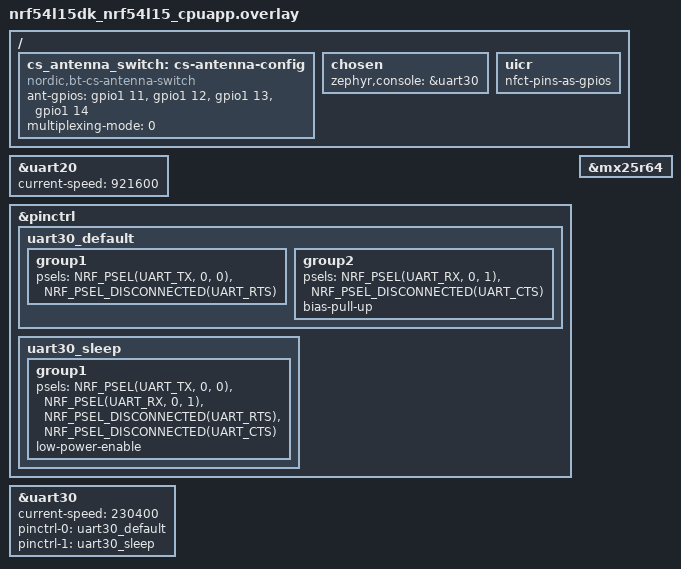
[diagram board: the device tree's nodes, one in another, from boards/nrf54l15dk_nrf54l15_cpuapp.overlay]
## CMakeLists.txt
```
#
# Copyright (c) 2024 Nordic Semiconductor
#
# SPDX-License-Identifier: LicenseRef-Nordic-5-Clause
#

cmake_minimum_required(VERSION 3.20.0)

find_package(Zephyr REQUIRED HINTS $ENV{ZEPHYR_BASE})
project(301ini)
# 自动查找 src/ 根目录下的所有 .c 文件
FILE(GLOB app_sources src/*.c)
# 手动添加 src/flash/ 子目录中的文件
FILE(GLOB flash_sources src/flash/*.c)
FILE(GLOB button_led_sources src/interface/*.c)

# NORDIC SDK APP START
target_sources(app PRIVATE
	${app_sources}
	${flash_sources}
	${button_led_sources}
)
# NORDIC SDK APP END
```

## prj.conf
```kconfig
#
# Copyright (c) 2024 Nordic Semiconductor ASA
#
# SPDX-License-Identifier: LicenseRef-Nordic-5-Clause
#
# 相对更底层的配置
CONFIG_SYSTEM_WORKQUEUE_STACK_SIZE=4096
CONFIG_MAIN_STACK_SIZE=4096
CONFIG_ASSERT=y

# 似乎是适用于官方DK和示例代码的配置
CONFIG_NCS_SAMPLES_DEFAULTS=y
CONFIG_DK_LIBRARY=y

# BT开头的一般都是蓝牙相关的配置
CONFIG_BT=y
CONFIG_BT_SMP=y
CONFIG_BT_CENTRAL=y
CONFIG_BT_MAX_CONN=1
CONFIG_BT_BONDABLE=n

CONFIG_BT_GATT_CLIENT=y
CONFIG_BT_GATT_DYNAMIC_DB=y

CONFIG_BT_CHANNEL_SOUNDING=y
CONFIG_BT_RAS=y
CONFIG_BT_RAS_RREQ=y

CONFIG_BT_SCAN=y
CONFIG_BT_SCAN_FILTER_ENABLE=y
CONFIG_BT_SCAN_UUID_CNT=1

# The Ranging Profile recommends a MTU of at least 247 octets.
CONFIG_BT_L2CAP_TX_MTU=498
CONFIG_BT_BUF_ACL_TX_SIZE=502
CONFIG_BT_BUF_ACL_RX_SIZE=502
CONFIG_BT_ATT_PREPARE_COUNT=3
CONFIG_BT_CTLR_DATA_LENGTH_MAX=251

# This reduces RAM usage. Additional RAM is needed to support optional
# features such as mode 3 or multiantenna. Change or remove these if
# using those features
CONFIG_BT_RAS_MODE_3_SUPPORTED=n
CONFIG_BT_RAS_MAX_ANTENNA_PATHS=1
CONFIG_BT_CTLR_SDC_CS_MAX_ANTENNA_PATHS=1
CONFIG_BT_CTLR_SDC_CS_NUM_ANTENNAS=1
CONFIG_BT_CTLR_SDC_CS_STEP_MODE3=n

# This size assumes the largest step size is mode 2 with one antenna path:
# 12 bytes * 160 steps in a subevent. Change or remove this if using mode 3
# or multiantenna.
CONFIG_BT_CHANNEL_SOUNDING_REASSEMBLY_BUFFER_SIZE=1920

# This allows CS and ACL to use different PHYs
CONFIG_BT_TRANSMIT_POWER_CONTROL=y

# This improves the performance of floating-point operations
CONFIG_FPU=y
CONFIG_FPU_SHARING=y

CONFIG_CBPRINTF_FP_SUPPORT=y

CONFIG_BT_CS_DE=y
CONFIG_BT_CS_DE_512_NFFT=y

# Console
CONFIG_CONSOLE=y
CONFIG_UART_CONSOLE=y
CONFIG_RTT_CONSOLE=n

# 这是启用非阻塞异步日志输出的
# 0 OFF
# 1 ERROR
# 2 WARNING
# 3 INFO
# 4 DEBUG
CONFIG_LOG=y
CONFIG_LOG_DEFAULT_LEVEL=3
CONFIG_LOG_MODE_DEFERRED=y
CONFIG_LOG_BACKEND_UART=y
CONFIG_LOG_BUFFER_SIZE=65536     
CONFIG_LOG_PROCESS_TRIGGER_THRESHOLD=256
CONFIG_LOG_PRINTK=y

CONFIG_LOG_BACKEND_RTT=n
CONFIG_LOG_BACKEND_UART=y
CONFIG_LOG_MODE_MINIMAL=y
CONFIG_LOG_MODE_IMMEDIATE=y

CONFIG_BT_CTLR_TX_PWR_PLUS_8=y
# 启用flash
CONFIG_FLASH=y

# QSPI Flash DMA配置
CONFIG_DMA=y
# CONFIG_NRFX_QSPI=y
# CONFIG_NRFX_QSPI_DMA=y

# Flash与蓝牙同步优化配置
CONFIG_SOC_FLASH_NRF_RADIO_SYNC_MPSL=y
CONFIG_MPSL_TIMESLOT_SESSION_COUNT=2

# Flash性能优化
# CONFIG_FLASH_PAGE_LAYOUT=y
# CONFIG_FLASH_MAP=y
# CONFIG_FLASH_HAS_DRIVER_ENABLED=y
```

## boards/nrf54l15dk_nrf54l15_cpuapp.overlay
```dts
/*
 * Copyright (c) 2025 Nordic Semiconductor ASA
 *
 * SPDX-License-Identifier: LicenseRef-Nordic-5-Clause
 */

/ {
	cs_antenna_switch: cs-antenna-config {
		status = "okay";
		compatible = "nordic,bt-cs-antenna-switch";
		ant-gpios = <&gpio1 11 (GPIO_ACTIVE_HIGH)>,
			    <&gpio1 12 (GPIO_ACTIVE_HIGH)>,
			    <&gpio1 13 (GPIO_ACTIVE_HIGH)>,
			    <&gpio1 14 (GPIO_ACTIVE_HIGH)>;
		multiplexing-mode = <0>;
	};

	chosen {
		/delete-property/ zephyr,console;
		/delete-property/ zephyr,shell-uart;
		/delete-property/ zephyr,uart-mcumgr;
		/delete-property/ zephyr,bt-mon-uart;
		/delete-property/ zephyr,bt-c2h-uart;
		zephyr,console = &uart30;
	};

	uicr { 
		nfct-pins-as-gpios; 
	};
};

&uart20 {
	current-speed = <921600>;
};

&pinctrl {
	uart30_default: uart30_default {
		group1 {
			psels = <NRF_PSEL(UART_TX, 0, 0)>,
			<NRF_PSEL_DISCONNECTED(UART_RTS)>;
		};
		group2 {
			psels = <NRF_PSEL(UART_RX, 0, 1)>,
			<NRF_PSEL_DISCONNECTED(UART_CTS)>;
			bias-pull-up;
		};
	};

	uart30_sleep: uart30_sleep {
		group1 {
			psels = <NRF_PSEL(UART_TX, 0, 0)>,
				<NRF_PSEL(UART_RX, 0, 1)>,
				<NRF_PSEL_DISCONNECTED(UART_RTS)>,
				<NRF_PSEL_DISCONNECTED(UART_CTS)>;
			low-power-enable;
		};
	};
};


&uart30 {
	current-speed = <230400>;
	pinctrl-0 = <&uart30_default>;
	pinctrl-1 = <&uart30_sleep>;
	pinctrl-names = "default", "sleep";
	/delete-property/ rts-pin;
	/delete-property/ cts-pin;	
	status = "okay";
};
&mx25r64 {
	status = "okay";

};
```

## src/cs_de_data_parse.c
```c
#include "cs_de_data_parse.h"
#include <bluetooth/cs_de.h>
#include <zephyr/logging/log.h>

LOG_MODULE_REGISTER(step_data_parse, CONFIG_LOG_DEFAULT_LEVEL);

void print_report(const cs_de_report_t *r, int max_output_channels) {
  // 内联role、quality、tone的字符串转换
  const char *role_str;
  switch (r->role) {
  case BT_CONN_LE_CS_ROLE_INITIATOR:
    role_str = "INITIATOR";
    break;
  case BT_CONN_LE_CS_ROLE_REFLECTOR:
    role_str = "REFLECTOR";
    break;
  default:
    role_str = "UNKNOWN";
    break;
  }

  LOG_INF("role=%s, n_ap=%d", role_str, r->n_ap);
  LOG_INF("rtt_accumulated_half_ns=%d, rtt_count=%d",
          r->rtt_accumulated_half_ns, r->rtt_count);

  for (int ap = 0; ap < r->n_ap; ap++) {
    const char *tone_str = (r->tone_quality[ap] == CS_DE_TONE_QUALITY_OK) ? "OK"
                           : (r->tone_quality[ap] == CS_DE_TONE_QUALITY_BAD)
                               ? "BAD"
                               : "UNKNOWN";
    LOG_INF("-- Antenna Path %d --", ap);
    LOG_INF("  Tone quality: %s", tone_str);
    LOG_INF("  Distance (ifft/phase_slope/rtt/best): %.3f / %.3f / %.3f / %.3f",
            r->distance_estimates[ap].ifft,
            r->distance_estimates[ap].phase_slope,
            r->distance_estimates[ap].rtt, r->distance_estimates[ap].best);
    for (int ch = 0; ch < max_output_channels; ch++) {
      LOG_INF(
          "  IQ[%d]: i_local=%.5f, q_local=%.5f, i_remote=%.5f, q_remote=%.5f",
          ch, r->iq_tones[ap].i_local[ch], r->iq_tones[ap].q_local[ch],
          r->iq_tones[ap].i_remote[ch], r->iq_tones[ap].q_remote[ch]);
    }
  }
}

void print_store_cs_de_report(const store_cs_de_report_t *s,
                              int max_output_channels) {
  LOG_INF("== store_cs_de_report_t ==");
  LOG_INF("report_index: %u", s->report_index);
  LOG_INF("timestamp_ms: %llu", s->timestamp_ms);
  print_report(&s->report, max_output_channels);
}

void store_cs_de_report(cs_de_report_t *p_report) {
  // 存储原始数据
  // 存储原始数据
}

void print_report_basic(const cs_de_report_t *r, int max_output_channels) {
  // 内联role、quality、tone的字符串转换
  const char *role_str;
  switch (r->role) {
  case BT_CONN_LE_CS_ROLE_INITIATOR:
    role_str = "INITIATOR";
    break;
  case BT_CONN_LE_CS_ROLE_REFLECTOR:
    role_str = "REFLECTOR";
    break;
  default:
    role_str = "UNKNOWN";
    break;
  }

  LOG_INF("role=%s, n_ap=%d, rtt_accumulated_half_ns=%d, rtt_count=%d",
          role_str, r->n_ap, r->rtt_accumulated_half_ns, r->rtt_count);

  for (int ap = 0; ap < r->n_ap; ap++) {
    const char *tone_str = (r->tone_quality[ap] == CS_DE_TONE_QUALITY_OK) ? "OK"
                           : (r->tone_quality[ap] == CS_DE_TONE_QUALITY_BAD)
                               ? "BAD"
                               : "UNKNOWN";
    
    LOG_INF("AP%d: quality=%s, dist(ifft/phase/rtt/best)=%.3f/%.3f/%.3f/%.3f",
            ap, tone_str,
            r->distance_estimates[ap].ifft,
            r->distance_estimates[ap].phase_slope,
            r->distance_estimates[ap].rtt, 
            r->distance_estimates[ap].best);
    
    // 分块打印IQ数据，避免缓冲区溢出
    const int channels_per_line = 8; // 每行8个通道
    const int max_buffer_size = 256; // 安全的缓冲区大小
    
    for (int ch_start = 0; ch_start < max_output_channels; ch_start += channels_per_line) {
      char iq_buffer[max_buffer_size];
      int offset = 0;
      
      offset += snprintf(iq_buffer + offset, sizeof(iq_buffer) - offset, 
                        "AP%d IQ[%d-%d]: ", ap, ch_start, 
                        (ch_start + channels_per_line - 1 < max_output_channels) ? 
                        ch_start + channels_per_line - 1 : max_output_channels - 1);
      
      int ch_end = (ch_start + channels_per_line < max_output_channels) ? 
                   ch_start + channels_per_line : max_output_channels;
      
      for (int ch = ch_start; ch < ch_end; ch++) {
        if (ch > ch_start) {
          offset += snprintf(iq_buffer + offset, sizeof(iq_buffer) - offset, " | ");
        }
        offset += snprintf(iq_buffer + offset, sizeof(iq_buffer) - offset,
                          "ch%d(i%.1f,q%.1f,i%.1f,q%.1f)", 
                          ch,
                          r->iq_tones[ap].i_local[ch],
                          r->iq_tones[ap].q_local[ch],
                          r->iq_tones[ap].i_remote[ch],
                          r->iq_tones[ap].q_remote[ch]);
      }
      
      LOG_INF("%s", iq_buffer);
    }
  }
}

void print_store_cs_de_report_basic(const store_cs_de_report_t *s,
                                   int max_output_channels) {
  LOG_INF("== Basic Report == index:%llu, timestamp:%llu", 
          s->report_index, s->timestamp_ms);
  print_report_fast(&s->report, max_output_channels);
  LOG_INF("== End Report ==");
}


#define IQ_LINE_CHUNK 512     // 单次输出最大字节数，按需调整
#define IQ_PRECISION 1        // 小数位数，1 位更紧凑更快
void print_report_fast(const cs_de_report_t *r, int max_output_channels) {
  // 内联role、quality、tone的字符串转换
  const char *role_str;
  switch (r->role) {
  case BT_CONN_LE_CS_ROLE_INITIATOR:
    role_str = "INITIATOR";
    break;
  case BT_CONN_LE_CS_ROLE_REFLECTOR:
    role_str = "REFLECTOR";
    break;
  default:
    role_str = "UNKNOWN";
    break;
  }

  LOG_INF("role=%s, n_ap=%d", role_str, r->n_ap);
  LOG_INF("rtt_accumulated_half_ns=%d, rtt_count=%d",
          r->rtt_accumulated_half_ns, r->rtt_count);

  for (int ap = 0; ap < r->n_ap; ap++) {
    const char *tone_str = (r->tone_quality[ap] == CS_DE_TONE_QUALITY_OK) ? "OK"
                           : (r->tone_quality[ap] == CS_DE_TONE_QUALITY_BAD)
                               ? "BAD"
                               : "UNKNOWN";
    LOG_INF("-- Antenna Path %d --", ap);
    LOG_INF("Tone=%s Dist(ifft/phase_slope/rtt/best)=%.3f/%.3f/%.3f/%.3f",
            tone_str,
            r->distance_estimates[ap].ifft,
            r->distance_estimates[ap].phase_slope,
            r->distance_estimates[ap].rtt,
            r->distance_estimates[ap].best);

    // 紧凑的 IQ 多信道合并输出
    char buf[IQ_LINE_CHUNK];
    size_t off = 0;

    // 先输出一个前缀，便于解析（可选）
    int n = snprintk(buf + off, sizeof(buf) - off, "IQ: ");
    if (n < 0) {
      // 格式化错误，直接跳过本 ap
      continue;
    }
    off += (size_t)n;

    for (int ch = 0; ch < max_output_channels; ch++) {
      // 每个信道的紧凑片段；为减少体积与格式化开销，默认 1 位小数
      n = snprintk(
          buf + off, sizeof(buf) - off,
          // "ch:%d,il:%.*f,ql:%.*f,ir:%.*f,qr:%.*f;",
          "ch:%d:%.*f,%.*f,%.*f,%.*f;",
          ch,
          IQ_PRECISION, r->iq_tones[ap].i_local[ch],
          IQ_PRECISION, r->iq_tones[ap].q_local[ch],
          IQ_PRECISION, r->iq_tones[ap].i_remote[ch],
          IQ_PRECISION, r->iq_tones[ap].q_remote[ch]);

      if (n < 0) {
        // 格式化错误，提前结束
        break;
      }

      // 如果这次写入会溢出缓冲区，先把已有内容打出去，再把当前信道重写入
      if ((size_t)n >= sizeof(buf) - off) {
        buf[off] = '\0';
        LOG_INF("%s", buf);
        off = 0;

        // 重新写入当前信道
        n = snprintk(
            buf + off, sizeof(buf) - off,
            // "ch:%d,il:%.*f,ql:%.*f,ir:%.*f,qr:%.*f;",
            "ch:%d:%.*f,%.*f,%.*f,%.*f;",
            ch,
            IQ_PRECISION, r->iq_tones[ap].i_local[ch],
            IQ_PRECISION, r->iq_tones[ap].q_local[ch],
            IQ_PRECISION, r->iq_tones[ap].i_remote[ch],
            IQ_PRECISION, r->iq_tones[ap].q_remote[ch]);

        if (n < 0) {
          break;
        }
      }

      off += (size_t)n;
    }

    // flush 剩余内容
    if (off > 0) {
      buf[off] = '\0';
      LOG_INF("%s", buf);
    }
  }
}
```

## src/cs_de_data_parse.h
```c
#ifndef CS_DE_DATA_PARSE_H
#define CS_DE_DATA_PARSE_H

#include <bluetooth/cs_de.h>

typedef struct {
  uint64_t report_index; // 测距结果的索引
  uint64_t timestamp_ms; // 记录写入时的毫秒数
  cs_de_report_t report; // 原始测距结果
} store_cs_de_report_t;

void store_cs_de_report(cs_de_report_t *p_report);
void print_report(const cs_de_report_t *r, int max_output_channels);
void print_store_cs_de_report(const store_cs_de_report_t *s,
                              int max_output_channels);
void print_store_cs_de_report_basic(const store_cs_de_report_t *s,
                                   int max_output_channels);
void print_report_fast(const cs_de_report_t *r, int max_output_channels);

#endif
```

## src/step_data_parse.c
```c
#include "step_data_parse.h"
#include <bluetooth/cs_de.h>

void store_cs_de_report(cs_de_report_t *p_report)
{
    // 存储原始数据
    // 存储原始数据
}
```

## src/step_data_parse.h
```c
#ifndef STEP_DATA_PARSE_H
#define STEP_DATA_PARSE_H

#include <bluetooth/cs_de.h>

void store_cs_de_report(cs_de_report_t *p_report);

#endif
```
